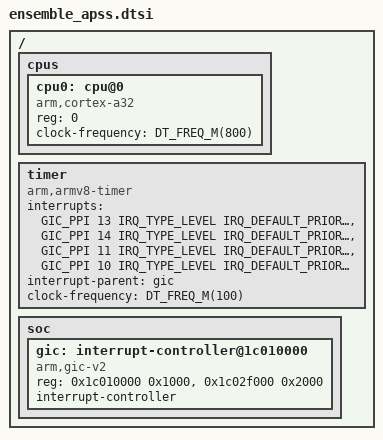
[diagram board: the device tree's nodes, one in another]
/*
 * SPDX-FileCopyrightText: Copyright Alif Semiconductor
 * SPDX-License-Identifier: Apache-2.0
 */

#include <arm/armv8-a.dtsi>
#include <zephyr/dt-bindings/interrupt-controller/arm-gic.h>
#include <freq.h>

/ {
	cpus {
		#address-cells = <1>;
		#size-cells = <0>;

		cpu0: cpu@0 {
			device_type = "cpu";
			compatible = "arm,cortex-a32";
			reg = <0>;
			clock-frequency = <DT_FREQ_M(800)>;
		};
	};

	timer {
		compatible = "arm,armv8-timer";
		interrupts = <GIC_PPI 13 IRQ_TYPE_LEVEL IRQ_DEFAULT_PRIORITY>,
			     <GIC_PPI 14 IRQ_TYPE_LEVEL IRQ_DEFAULT_PRIORITY>,
			     <GIC_PPI 11 IRQ_TYPE_LEVEL IRQ_DEFAULT_PRIORITY>,
			     <GIC_PPI 10 IRQ_TYPE_LEVEL IRQ_DEFAULT_PRIORITY>;
		interrupt-parent = <&gic>;
		clock-frequency = <DT_FREQ_M(100)>;
	};

	soc {
		gic: interrupt-controller@1c010000 {
			compatible = "arm,gic-v2", "arm,gic";
			reg = <0x1c010000 0x1000>, /* GICD */
			      <0x1c02f000 0x2000>; /* GICC */
			interrupt-controller;
			#interrupt-cells = <4>;
			status = "okay";
		};
	};
};
